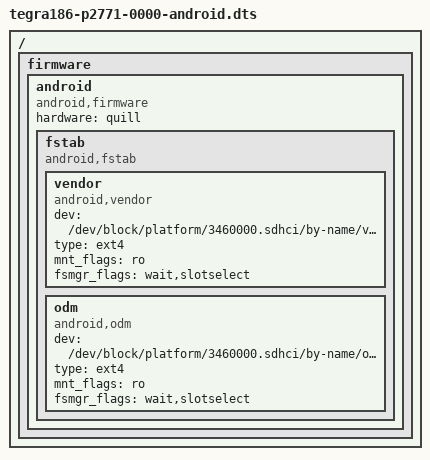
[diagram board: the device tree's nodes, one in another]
// SPDX-License-Identifier: GPL-2.0
/dts-v1/;

#include "tegra186-p2771-0000.dts"

/ {
	firmware {
		android {
			compatible = "android,firmware";
			hardware = "quill";
			fstab {
				compatible = "android,fstab";
				vendor {
					compatible = "android,vendor";
					dev = "/dev/block/platform/3460000.sdhci/by-name/vendor";
					type = "ext4";
					mnt_flags = "ro";
					fsmgr_flags = "wait,slotselect";
				};
				odm {
					compatible = "android,odm";
					dev = "/dev/block/platform/3460000.sdhci/by-name/odm";
					type = "ext4";
					mnt_flags = "ro";
					fsmgr_flags = "wait,slotselect";
				};
			};
		};
	};
};
